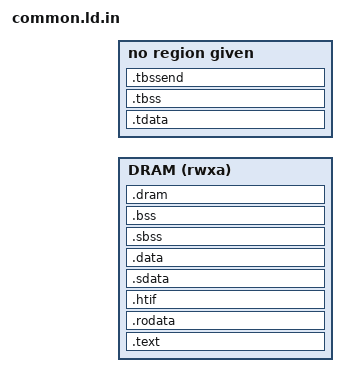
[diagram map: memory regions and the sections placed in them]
/* Copyright 2020 ETH Zurich and University of Bologna. */
/* Solderpad Hardware License, Version 0.51, see LICENSE for details. */
/* SPDX-License-Identifier: SHL-0.51 */

OUTPUT_ARCH( "riscv" )
ENTRY(_start)

MEMORY
{
    DRAM (rwxa)  : ORIGIN = @MEM_DRAM_ORIGIN@, LENGTH = @MEM_DRAM_SIZE@
}

SECTIONS
{
  /* The program code and other data goes into DRAM */
  .text :
  {
    . = ALIGN(4);
    *(.init)
    *(.text.startup)
    *(.text)
    *(.text*)
    . = ALIGN(4);
    _etext = .;
  } >DRAM

  .rodata :
  {
    . = ALIGN(4);
    *(.rodata)
    *(.rodata*)
    . = ALIGN(4);
  } >DRAM

  /* HTIF */
  .htif         : { } >DRAM

  /* Thread Local Storage sections  */
  .tdata    :
  {
    __tdata_start = .;
    *(.tdata .tdata.* .gnu.linkonce.td.*)
    __tdata_end = .;
  }
  .tbss :
  {
    __tbss_start = .;
    *(.tbss .tbss.* .gnu.linkonce.tb.*)
    *(.tcommon)
    __tbss_end = .;
  }
  /* add a section after .tbss to put the __tbss_end symbol into for
     the LLD linker */
  .tbssend : { __tbss_end2 = .; }

  /* used by the startup to initialize data */
  _sidata = LOADADDR(.data);

  /* small data section that can be addressed through the global pointer */
  .sdata          :
  {
    __SDATA_BEGIN__ = .;
    __global_pointer$ = . + 0x7f0;
    *(.srodata.cst16) *(.srodata.cst8) *(.srodata.cst4) *(.srodata.cst2) *(.srodata .srodata.*)
    *(.sdata .sdata.* .gnu.linkonce.s.*)
  } >DRAM

  /* Initialized data sections goes into DRAM */
  .data :
  {
    __DATA_BEGIN__ = .;
    *(.data .data.* .gnu.linkonce.d.*)
    SORT(CONSTRUCTORS)
  } >DRAM
  _edata = .; PROVIDE (edata = .);

  /* small bss section */
  . = .;
  __bss_start = .;
  .sbss           :
  {
    *(.dynsbss)
    *(.sbss .sbss.* .gnu.linkonce.sb.*)
    *(.scommon)
  } >DRAM

  /* Uninitialized data section */
  .bss            :
  {
   *(.dynbss)
   *(.bss .bss.* .gnu.linkonce.b.*)
   *(COMMON)
   /* Align here to ensure that the .bss section occupies space up to
      _end.  Align after .bss to ensure correct alignment even if the
      .bss section disappears because there are no input sections. */
   . = ALIGN(. != 0 ? 32 / 8 : 1);
  } >DRAM
  . = ALIGN(32 / 8);
  . = SEGMENT_START("ldata-segment", .);
  . = ALIGN(32 / 8);
  __BSS_END__ = .;
  _end = .; PROVIDE (end = .);

  /* Uninitialized data section in DRAM */
  .dram :
  {
    *(.dram)
    _edram = .;
  } >DRAM
}

/* Last valid byte of the DRAM region. Used by snrt_l3alloc to bound the L3
 * heap. We use (... + LENGTH - 1) rather than (... + LENGTH) so the result
 * stays within uint32_t when DRAM spans the full upper 2GB (otherwise the
 * symbol address wraps to 0, which both breaks arithmetic in C and triggers
 * clang's "address of a declared object is never NULL" optimization). */
__l3_end = ORIGIN(DRAM) + LENGTH(DRAM) - 1;
